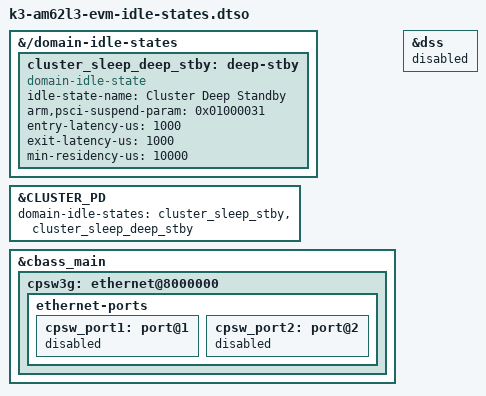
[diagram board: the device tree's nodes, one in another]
// SPDX-License-Identifier: GPL-2.0-or-later OR MIT
/**
 * DT overlay which adds deep standby idle states to the AM62L3 EVM.
 *
 * This enables the deep standby power state the cluster for aggressive
 * power savings.
 *
 * [NOTE: This overlay disables the CPSW driver and Display driver due
 *        incompatibility of deep standby sequence with these drivers ]
 *
 * Copyright (C) 2026 Texas Instruments Incorporated - https://www.ti.com/
 */

/dts-v1/;
/plugin/;

&{/domain-idle-states} {
	cluster_sleep_deep_stby: deep-stby {
		compatible = "domain-idle-state";
		idle-state-name = "Cluster Deep Standby";
		arm,psci-suspend-param = <0x01000031>;
		entry-latency-us = <1000>;
		exit-latency-us = <1000>;
		min-residency-us = <10000>;
	};
};

&CLUSTER_PD {
	domain-idle-states = <&cluster_sleep_stby>, <&cluster_sleep_deep_stby>;
};

/*
 * HACK : Disable CPSW ethernet driver and Display driver
 * The standby state mode decreases the CBASS frequency to 125Mhz.
 * The CPSW driver is sensitive to CBASS clock and this change causes harware CRC errors.
 * This is a workaround to prevent issues when standby is enabled.
 *
 * The standby mode also enables DDR Auto self-refresh. This causes Plane-underflow error
 * when Display is connected.
 * The tidss driver is disabled so as a workaround for this issue.
 */
&cbass_main {
	cpsw3g: ethernet@8000000 {
		ethernet-ports {
			cpsw_port1: port@1 {
				status = "disabled";
			};
			cpsw_port2: port@2 {
				status = "disabled";
			};
		};
	};
};

&dss {
        status = "disabled";
};
